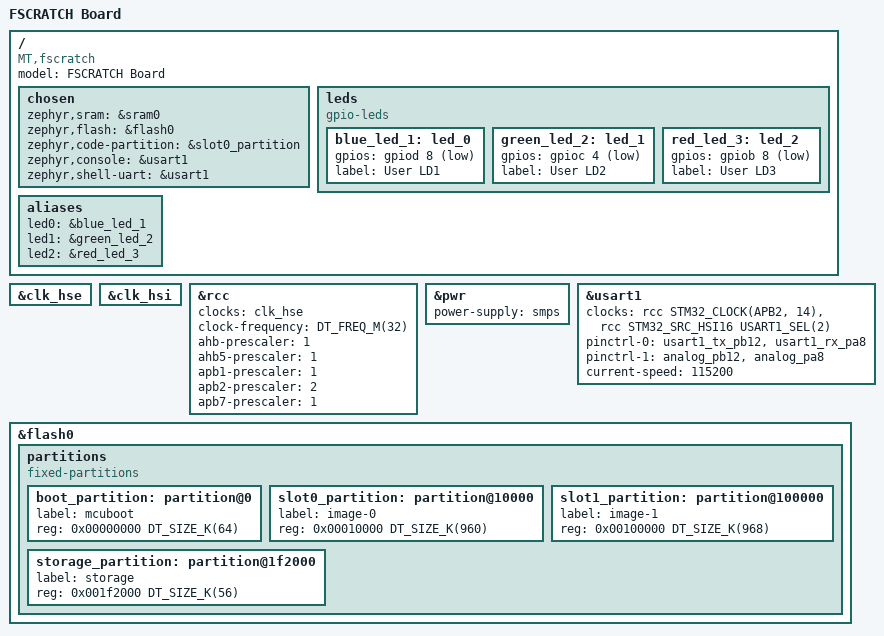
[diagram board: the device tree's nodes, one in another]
/dts-v1/;
#include <st/wba/stm32wba65Xi.dtsi>
#include <st/wba/stm32wba65rivx-pinctrl.dtsi>

/ {
    model = "FSCRATCH Board";
    compatible = "MT,fscratch";

    chosen {
        zephyr,sram = &sram0;
        zephyr,flash = &flash0;
        zephyr,code-partition = &slot0_partition;
		zephyr,console = &usart1;
    	zephyr,shell-uart = &usart1;
    };

    leds: leds {
		compatible = "gpio-leds";

		blue_led_1: led_0 {
			gpios = <&gpiod 8 GPIO_ACTIVE_LOW>;
			label = "User LD1";
		};

		green_led_2: led_1 {
			gpios = <&gpioc 4 GPIO_ACTIVE_LOW>;
			label = "User LD2";
		};

		red_led_3: led_2 {
			gpios = <&gpiob 8 GPIO_ACTIVE_LOW>;
			label = "User LD3";
        };
    };

    aliases {
		led0 = &blue_led_1;
		led1 = &green_led_2;
		led2 = &red_led_3;
	};
};

/* Required for RCC */
&clk_hse {
	status = "okay";

	/*
	 * Disable HSE trim applied by Clock Control.
	 * Board-specific init will apply trim from OTP.
	 */
	/delete-property/ hse-trimming;
};
/* Required for UART -> STM32_SRC_HSI16*/
&clk_hsi {
	status = "okay";
};

/* Required */
&rcc {
	clocks = <&clk_hse>;
	clock-frequency = <DT_FREQ_M(32)>; /* Lowest value to manage radio events */
	ahb-prescaler = <1>;
	ahb5-prescaler = <1>;
	apb1-prescaler = <1>;
	apb2-prescaler = <2>;
	apb7-prescaler = <1>;
};

/* Required */
&pwr {
	power-supply = "smps";
};

&usart1 {
	clocks = <&rcc STM32_CLOCK(APB2, 14)>,
		 <&rcc STM32_SRC_HSI16 USART1_SEL(2)>;
	pinctrl-0 = <&usart1_tx_pb12 &usart1_rx_pa8>;
	pinctrl-1 = <&analog_pb12 &analog_pa8>;
	pinctrl-names = "default", "sleep";
	current-speed = <115200>;
	status = "okay";
};

&flash0 {
	partitions {
		compatible = "fixed-partitions";
		#address-cells = <1>;
		#size-cells = <1>;

		boot_partition: partition@0 {
			label = "mcuboot";
			reg = <0x00000000 DT_SIZE_K(64)>;
		};

		slot0_partition: partition@10000 {
			label = "image-0";
			reg = <0x00010000 DT_SIZE_K(960)>;
		};

		slot1_partition: partition@100000 {
			label = "image-1";
			reg = <0x00100000 DT_SIZE_K(968)>;
		};

		storage_partition: partition@1f2000 {
			label = "storage";
			reg = <0x001f2000 DT_SIZE_K(56)>;
		};
	};
};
